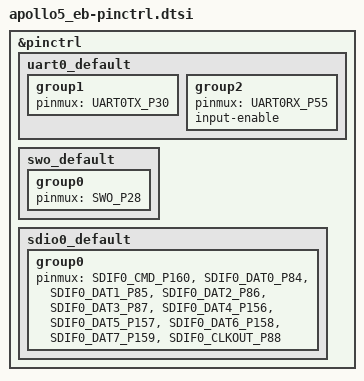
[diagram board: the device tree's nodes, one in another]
/*
 * Copyright (c) 2024 Ambiq Micro Inc.
 *
 * SPDX-License-Identifier: Apache-2.0
 */

#include <apollo5/ambiq-apollo5-pinmux.h>

&pinctrl {
	uart0_default: uart0_default {
		group1 {
			pinmux = <UART0TX_P30>;
		};
		group2 {
			pinmux = <UART0RX_P55>;
			input-enable;
		};
	};
	swo_default: swo_default {
		group0 {
			pinmux = <SWO_P28>;
		};
	};
	sdio0_default: sdio0_default {
		group0 {
			pinmux = <SDIF0_CMD_P160>,
				 <SDIF0_DAT0_P84>,
				 <SDIF0_DAT1_P85>,
				 <SDIF0_DAT2_P86>,
				 <SDIF0_DAT3_P87>,
				 <SDIF0_DAT4_P156>,
				 <SDIF0_DAT5_P157>,
				 <SDIF0_DAT6_P158>,
				 <SDIF0_DAT7_P159>,
				 <SDIF0_CLKOUT_P88>;
		};
	};
};
